# STM32H735ZGT6 register map
File version: 1.0
Registers are 32-bit, access not given, reset 0x0 unless marked. A register's access mark holds for its fields unless they carry their own. Offsets are from the block's base; [hi:lo] are bit positions; {n}, {i} and the like mark numbered series.

## IWDG1
Base 0x58004800
0x00 KR
  [15:0] KEY
0x04 PR
  [2:0] PR
0x08 RLR
  [11:0] RL
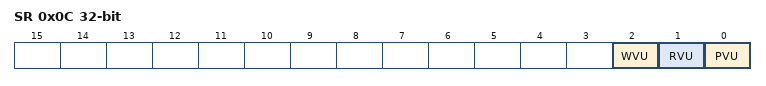
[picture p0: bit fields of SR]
0x0C SR
  [2] WVU, [1] RVU, [0] PVU
0x10 WINR
  [11:0] WIN

## DTS
Base 0x58006800
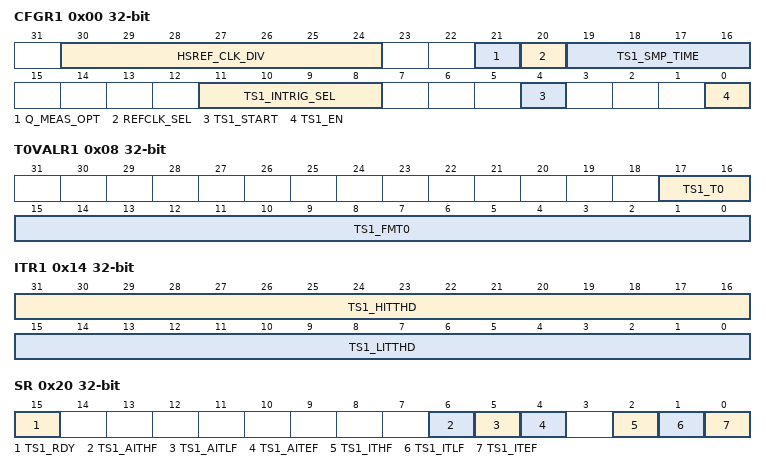
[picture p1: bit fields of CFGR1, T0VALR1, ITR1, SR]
0x00 CFGR1
  [30:24] HSREF_CLK_DIV, [21] Q_MEAS_OPT, [20] REFCLK_SEL, [19:16] TS1_SMP_TIME, [11:8] TS1_INTRIG_SEL, [4] TS1_START, [0] TS1_EN
0x08 T0VALR1
  [17:16] TS1_T0, [15:0] TS1_FMT0
0x10 RAMPVALR
  [15:0] TS1_RAMP_COEFF
0x14 ITR1
  [31:16] TS1_HITTHD, [15:0] TS1_LITTHD
0x1C DR
  [15:0] TS1_MFREQ
0x20 SR
  [15] TS1_RDY, [6] TS1_AITHF, [5] TS1_AITLF, [4] TS1_AITEF, [2] TS1_ITHF, [1] TS1_ITLF, [0] TS1_ITEF
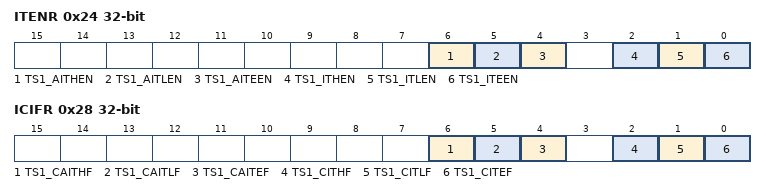
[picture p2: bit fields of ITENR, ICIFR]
0x24 ITENR
  [6] TS1_AITHEN, [5] TS1_AITLEN, [4] TS1_AITEEN, [2] TS1_ITHEN, [1] TS1_ITLEN, [0] TS1_ITEEN
0x28 ICIFR
  [6] TS1_CAITHF, [5] TS1_CAITLF, [4] TS1_CAITEF, [2] TS1_CITHF, [1] TS1_CITLF, [0] TS1_CITEF
0x2C OR

## GPIOA
Base 0x58020000
Same registers: GPIOB 0x58020400, GPIOC 0x58020800, GPIOD 0x58020C00, GPIOE 0x58021000, GPIOF 0x58021400, GPIOG 0x58021800, GPIOH 0x58021C00, GPIOJ 0x58022400, GPIOK 0x58022800
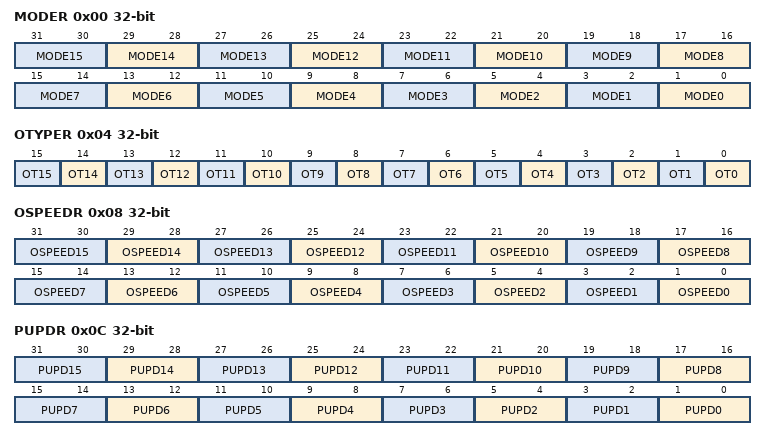
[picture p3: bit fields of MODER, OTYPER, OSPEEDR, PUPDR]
0x00 MODER
  [2n+1:2n] MODE{n} (n=0..15)
0x04 OTYPER
  [n] OT{n} (n=0..15)
0x08 OSPEEDR
  [2n+1:2n] OSPEED{n} (n=0..15)
0x0C PUPDR
  [2n+1:2n] PUPD{n} (n=0..15)
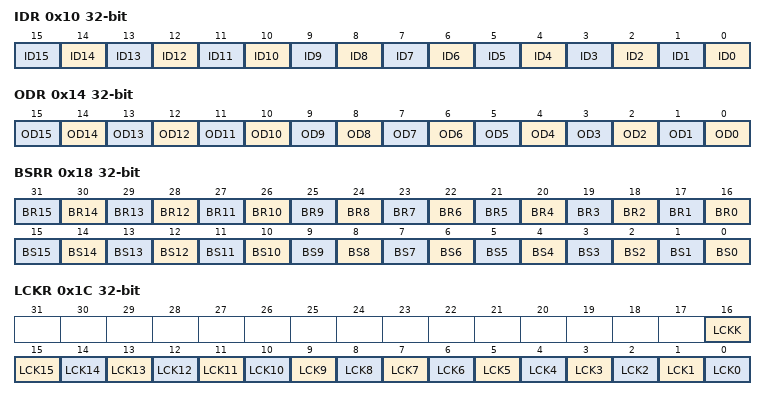
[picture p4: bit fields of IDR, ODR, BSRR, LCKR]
0x10 IDR
  [n] ID{n} (n=0..15)
0x14 ODR
  [n] OD{n} (n=0..15)
0x18 BSRR
  [n+16] BR{n} (n=0..15), [n] BS{n} (n=0..15)
0x1C LCKR
  [16] LCKK, [n] LCK{n} (n=0..15)
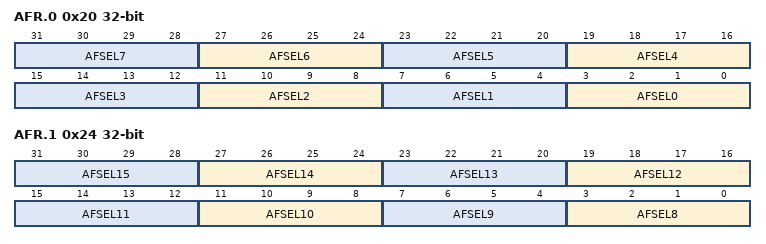
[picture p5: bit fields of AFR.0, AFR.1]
0x20 AFR.0
  [4n+3:4n] AFSEL{n} (n=0..7)
0x24 AFR.1
  [4n-29:4n-32] AFSEL{n} (n=8..15)

## PWR
Base 0x58024800
0x00 CR1
  [18] ALS_LEV2, [18:17] ALS_LEV3, [16] AVDEN, [15:14] SVOS, [9] FLPS, [8] DBP, [7] PLS_LEV4, [7:6] PLS_LEV6, [7:5] PLS_LEV7, [4] PVDEN, [0] LPDS
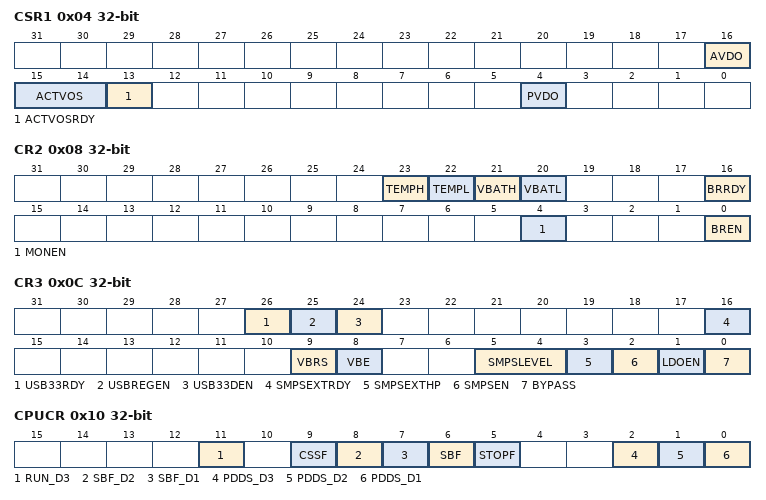
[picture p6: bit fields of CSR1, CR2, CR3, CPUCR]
0x04 CSR1
  [16] AVDO, [15:14] ACTVOS, [13] ACTVOSRDY, [4] PVDO
0x08 CR2
  [23] TEMPH, [22] TEMPL, [21] VBATH, [20] VBATL, [16] BRRDY, [4] MONEN, [0] BREN
0x0C CR3
  [26] USB33RDY, [25] USBREGEN, [24] USB33DEN, [16] SMPSEXTRDY, [9] VBRS, [8] VBE, [5:4] SMPSLEVEL, [3] SMPSEXTHP, [2] SMPSEN, [1] LDOEN, [0] BYPASS
0x10 CPUCR
  [11] RUN_D3, [9] CSSF, [8] SBF_D2, [7] SBF_D1, [6] SBF, [5] STOPF, [2] PDDS_D3, [1] PDDS_D2, [0] PDDS_D1
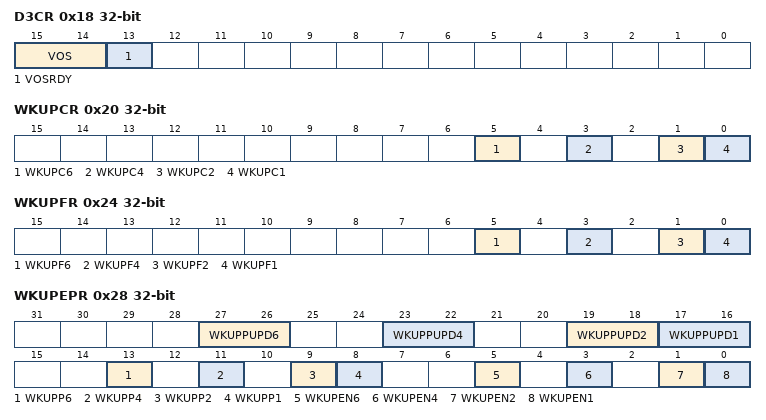
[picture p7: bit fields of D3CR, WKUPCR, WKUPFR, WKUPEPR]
0x18 D3CR
  [15:14] VOS, [13] VOSRDY
0x20 WKUPCR
  [5] WKUPC6, [3] WKUPC4, [1] WKUPC2, [0] WKUPC1
0x24 WKUPFR
  [5] WKUPF6, [3] WKUPF4, [1] WKUPF2, [0] WKUPF1
0x28 WKUPEPR
  [27:26] WKUPPUPD6, [23:22] WKUPPUPD4, [19:18] WKUPPUPD2, [17:16] WKUPPUPD1, [13] WKUPP6, [11] WKUPP4, [9] WKUPP2, [8] WKUPP1, [5] WKUPEN6, [3] WKUPEN4, [1] WKUPEN2, [0] WKUPEN1

## CRC
Base 0x58024C00
0x00 DR
0x04 IDR
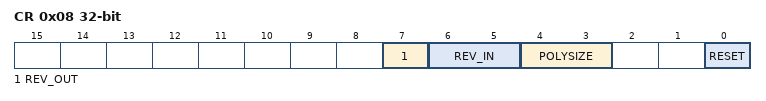
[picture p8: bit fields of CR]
0x08 CR
  [7] REV_OUT, [6:5] REV_IN, [4:3] POLYSIZE, [0] RESET
0x10 INIT
0x14 POL

## BDMA
Base 0x58025400
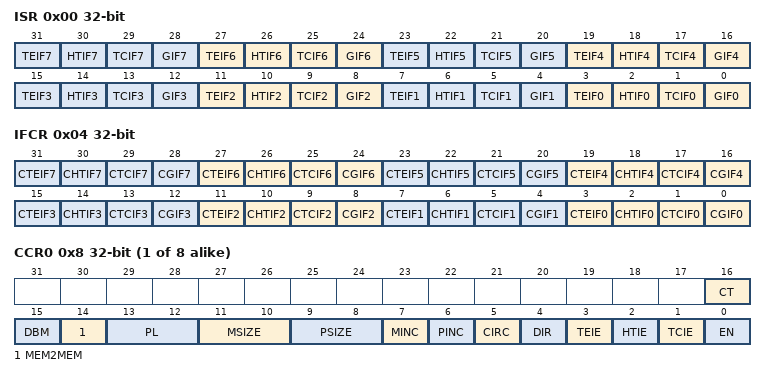
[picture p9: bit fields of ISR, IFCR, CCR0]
0x00 ISR
  [4n+3] TEIF{n} (n=0..7), [4n+2] HTIF{n} (n=0..7), [4n+1] TCIF{n} (n=0..7), [4n] GIF{n} (n=0..7)
0x04 IFCR
  [4n+3] CTEIF{n} (n=0..7), [4n+2] CHTIF{n} (n=0..7), [4n+1] CTCIF{n} (n=0..7), [4n] CGIF{n} (n=0..7)
{0x8+0x14*i} CCR{i} (i=0..7)
  [16] CT, [15] DBM, [14] MEM2MEM, [13:12] PL, [11:10] MSIZE, [9:8] PSIZE, [7] MINC, [6] PINC, [5] CIRC, [4] DIR, [3] TEIE, [2] HTIE, [1] TCIE, [0] EN
{0xC+0x14*i} CNDTR{i} (i=0..7)
  [15:0] NDT
{0x10+0x14*i} CPAR{i} (i=0..7)
  [31:0] PA
{0x14+0x14*i} CM0AR{i} (i=0..7)
  [31:0] MA
{0x18+0x14*i} CM1AR{i} (i=0..7)
  [31:0] MA

## HSEM
Base 0x58026400
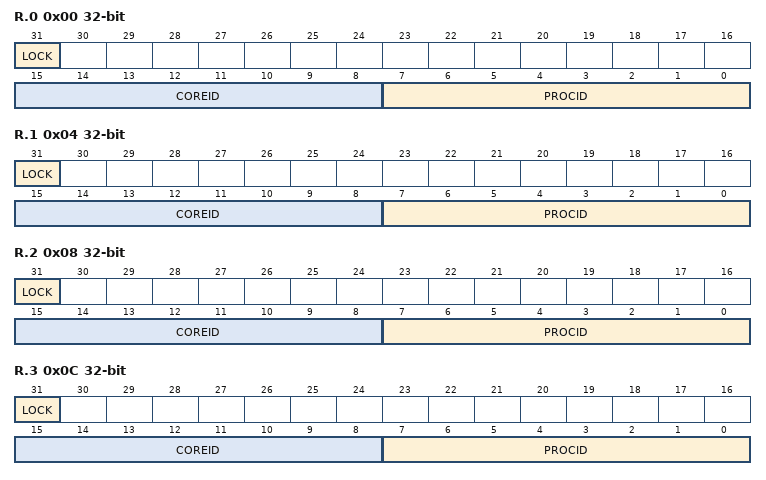
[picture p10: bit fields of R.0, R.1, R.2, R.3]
0x00 R.0
  [31] LOCK, [15:8] COREID, [7:0] PROCID
0x04 R.1
  [31] LOCK, [15:8] COREID, [7:0] PROCID
0x08 R.2
  [31] LOCK, [15:8] COREID, [7:0] PROCID
0x0C R.3
  [31] LOCK, [15:8] COREID, [7:0] PROCID
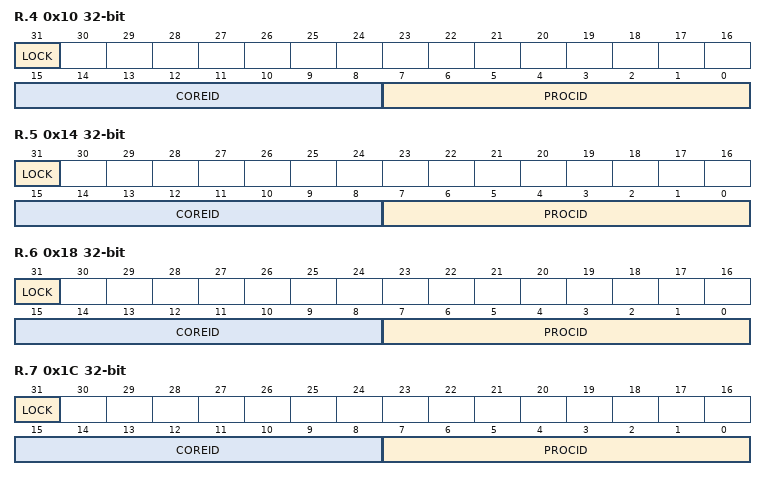
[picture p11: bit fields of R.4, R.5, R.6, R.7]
0x10 R.4
  [31] LOCK, [15:8] COREID, [7:0] PROCID
0x14 R.5
  [31] LOCK, [15:8] COREID, [7:0] PROCID
0x18 R.6
  [31] LOCK, [15:8] COREID, [7:0] PROCID
0x1C R.7
  [31] LOCK, [15:8] COREID, [7:0] PROCID
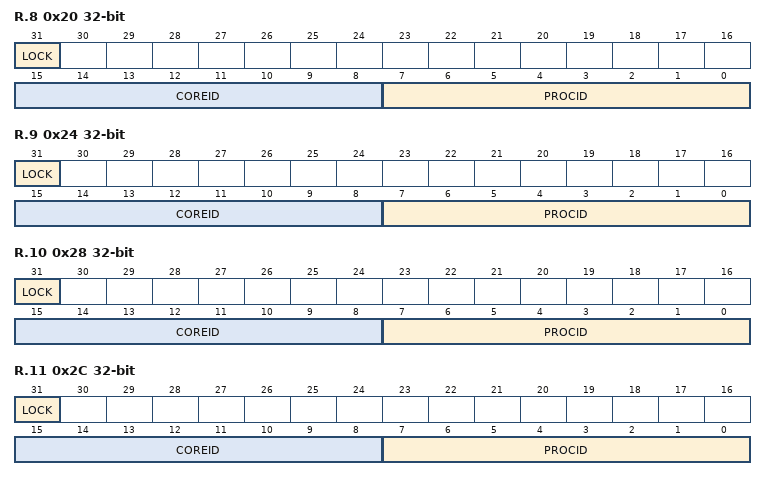
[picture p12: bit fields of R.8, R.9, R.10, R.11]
0x20 R.8
  [31] LOCK, [15:8] COREID, [7:0] PROCID
0x24 R.9
  [31] LOCK, [15:8] COREID, [7:0] PROCID
0x28 R.10
  [31] LOCK, [15:8] COREID, [7:0] PROCID
0x2C R.11
  [31] LOCK, [15:8] COREID, [7:0] PROCID
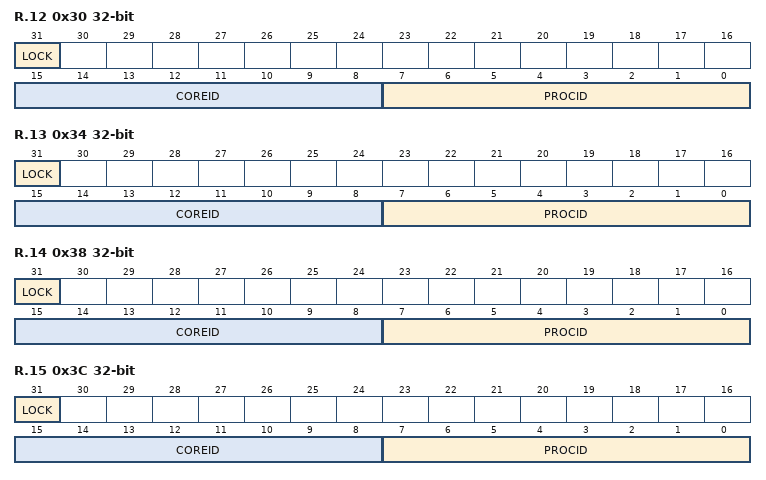
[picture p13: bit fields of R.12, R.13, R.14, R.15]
0x30 R.12
  [31] LOCK, [15:8] COREID, [7:0] PROCID
0x34 R.13
  [31] LOCK, [15:8] COREID, [7:0] PROCID
0x38 R.14
  [31] LOCK, [15:8] COREID, [7:0] PROCID
0x3C R.15
  [31] LOCK, [15:8] COREID, [7:0] PROCID
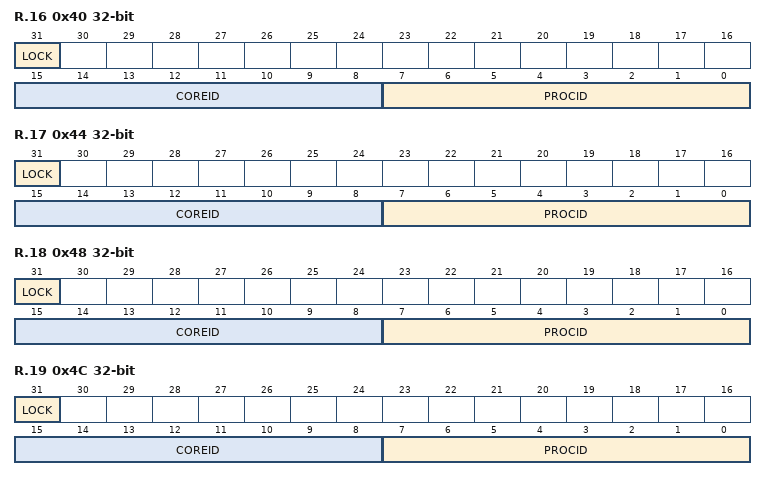
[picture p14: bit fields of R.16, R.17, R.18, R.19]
0x40 R.16
  [31] LOCK, [15:8] COREID, [7:0] PROCID
0x44 R.17
  [31] LOCK, [15:8] COREID, [7:0] PROCID
0x48 R.18
  [31] LOCK, [15:8] COREID, [7:0] PROCID
0x4C R.19
  [31] LOCK, [15:8] COREID, [7:0] PROCID
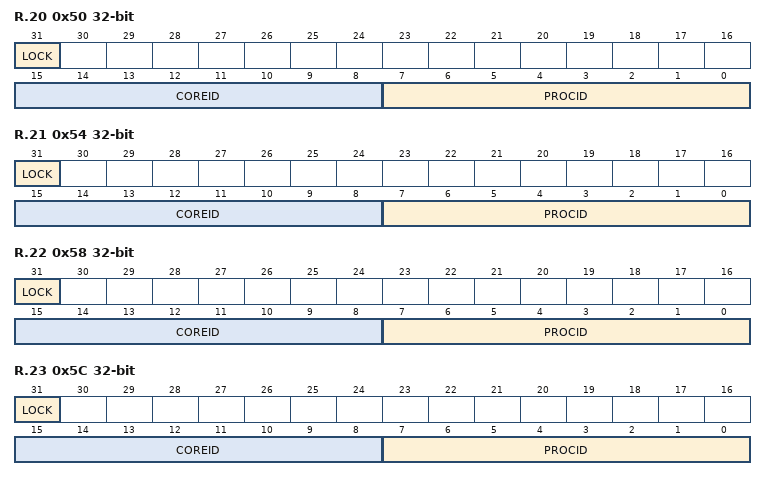
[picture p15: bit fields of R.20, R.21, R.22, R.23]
0x50 R.20
  [31] LOCK, [15:8] COREID, [7:0] PROCID
0x54 R.21
  [31] LOCK, [15:8] COREID, [7:0] PROCID
0x58 R.22
  [31] LOCK, [15:8] COREID, [7:0] PROCID
0x5C R.23
  [31] LOCK, [15:8] COREID, [7:0] PROCID
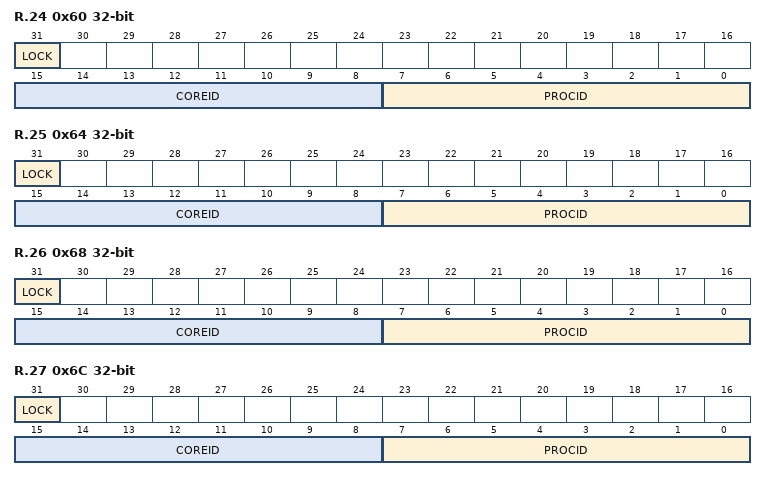
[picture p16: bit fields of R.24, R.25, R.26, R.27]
0x60 R.24
  [31] LOCK, [15:8] COREID, [7:0] PROCID
0x64 R.25
  [31] LOCK, [15:8] COREID, [7:0] PROCID
0x68 R.26
  [31] LOCK, [15:8] COREID, [7:0] PROCID
0x6C R.27
  [31] LOCK, [15:8] COREID, [7:0] PROCID
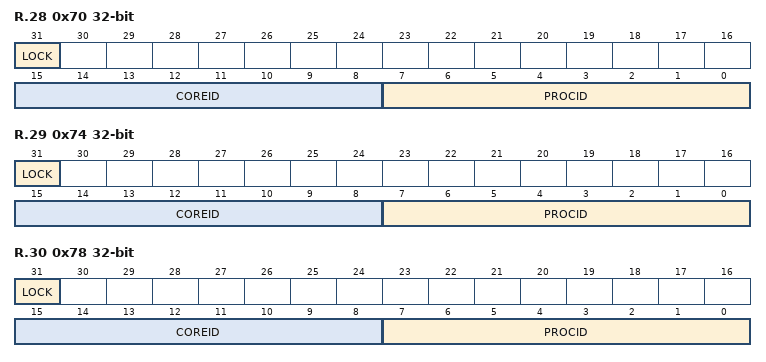
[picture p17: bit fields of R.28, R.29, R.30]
0x70 R.28
  [31] LOCK, [15:8] COREID, [7:0] PROCID
0x74 R.29
  [31] LOCK, [15:8] COREID, [7:0] PROCID
0x78 R.30
  [31] LOCK, [15:8] COREID, [7:0] PROCID
0x7C R.31
  [31] LOCK, [15:8] COREID, [7:0] PROCID
0x80 RLR.0
  [31] LOCK, [15:8] COREID, [7:0] PROCID
0x84 RLR.1
  [31] LOCK, [15:8] COREID, [7:0] PROCID
0x88 RLR.2
  [31] LOCK, [15:8] COREID, [7:0] PROCID
0x8C RLR.3
  [31] LOCK, [15:8] COREID, [7:0] PROCID
0x90 RLR.4
  [31] LOCK, [15:8] COREID, [7:0] PROCID
0x94 RLR.5
  [31] LOCK, [15:8] COREID, [7:0] PROCID
0x98 RLR.6
  [31] LOCK, [15:8] COREID, [7:0] PROCID
0x9C RLR.7
  [31] LOCK, [15:8] COREID, [7:0] PROCID
0xA0 RLR.8
  [31] LOCK, [15:8] COREID, [7:0] PROCID
0xA4 RLR.9
  [31] LOCK, [15:8] COREID, [7:0] PROCID
0xA8 RLR.10
  [31] LOCK, [15:8] COREID, [7:0] PROCID
0xAC RLR.11
  [31] LOCK, [15:8] COREID, [7:0] PROCID
0xB0 RLR.12
  [31] LOCK, [15:8] COREID, [7:0] PROCID
0xB4 RLR.13
  [31] LOCK, [15:8] COREID, [7:0] PROCID
0xB8 RLR.14
  [31] LOCK, [15:8] COREID, [7:0] PROCID
0xBC RLR.15
  [31] LOCK, [15:8] COREID, [7:0] PROCID
0xC0 RLR.16
  [31] LOCK, [15:8] COREID, [7:0] PROCID
0xC4 RLR.17
  [31] LOCK, [15:8] COREID, [7:0] PROCID
0xC8 RLR.18
  [31] LOCK, [15:8] COREID, [7:0] PROCID
0xCC RLR.19
  [31] LOCK, [15:8] COREID, [7:0] PROCID
0xD0 RLR.20
  [31] LOCK, [15:8] COREID, [7:0] PROCID
0xD4 RLR.21
  [31] LOCK, [15:8] COREID, [7:0] PROCID
0xD8 RLR.22
  [31] LOCK, [15:8] COREID, [7:0] PROCID
0xDC RLR.23
  [31] LOCK, [15:8] COREID, [7:0] PROCID
0xE0 RLR.24
  [31] LOCK, [15:8] COREID, [7:0] PROCID
0xE4 RLR.25
  [31] LOCK, [15:8] COREID, [7:0] PROCID
0xE8 RLR.26
  [31] LOCK, [15:8] COREID, [7:0] PROCID
0xEC RLR.27
  [31] LOCK, [15:8] COREID, [7:0] PROCID
0xF0 RLR.28
  [31] LOCK, [15:8] COREID, [7:0] PROCID
0xF4 RLR.29
  [31] LOCK, [15:8] COREID, [7:0] PROCID
0xF8 RLR.30
  [31] LOCK, [15:8] COREID, [7:0] PROCID
0xFC RLR.31
  [31] LOCK, [15:8] COREID, [7:0] PROCID
0x100 C1IER
  [n] ISE{n} (n=0..31)
0x104 C1ICR
  [n] ISC{n} (n=0..31)
0x108 C1ISR
  [n] ISF{n} (n=0..31)
0x10C C1MISR
  [n] MISF{n} (n=0..31)
0x140 CR
  [31:16] KEY, [15:8] COREID
0x144 KEYR
  [31:16] KEY

## HSEM_COMMON
Base 0x58026500
0x00 IER
0x04 ICR
0x08 ISR
0x0C MISR

## DBGMCU
Base 0x5C001000
0x00 IDCODE
  [31:16] REV_ID, [11:0] DEV_ID
0x04 CR
  [28] DBG_TRGOEN, [22] DBG_CKD3EN, [21] DBG_CKD1EN, [20] DBG_TRACECKEN, [8] DBG_STANDBYD3, [7] DBG_STOPD3, [2] DBG_STANDBYD1, [1] DBG_STOPD1, [0] DBG_SLEEPD1
0x34 APB3FZ1
  [6] DBG_WWDG1
0x3C APB1LFZ1
  [25] DBG_I2C5, [23] DBG_I2C3, [22] DBG_I2C2, [21] DBG_I2C1, [9] DBG_LPTIM1, [8] DBG_TIM14, [7] DBG_TIM13, [6] DBG_TIM12, [n-2] DBG_TIM{n} (n=2..7)
0x44 APB1HFZ1
  [24] DBG_TIM24
0x4C APB2FZ1
  [18] DBG_TIM17, [17] DBG_TIM16, [16] DBG_TIM15, [1] DBG_TIM8, [0] DBG_TIM1
0x54 APB4FZ1
  [18] DBG_IWDG1, [16] DBG_RTC, [n+7] DBG_LPTIM{n} (n=2..5), [7] DBG_I2C4
0xFD0 PIDR4
  [7:4] 4KCOUNT, [3:0] JEP106CON
0xFE0 PIDR0
  [7:0] PARTNUM
0xFE4 PIDR1
  [7:4] JEP106ID, [3:0] PARTNUM
0xFE8 PIDR2
  [7:4] REVISION, [3] JEDEC, [2:0] JEP106ID
0xFEC PIDR3
  [7:4] REVAND, [3:0] CMOD
{0xFF0+4i} CIDR{i} (i=0..3)
